# ATSAM4N16C device description
Architecture: CORTEX-M4; Family: SAM4; Series: SAM4N
Registers are 32-bit, read-write, no defined reset value unless marked. A register's access mark holds for its fields unless they carry their own. Offsets are from the block's base; [hi:lo] are bit positions; {n}, {i} and the like mark numbered series; 'fields as' and 'values as' point back to an identical list.

## TC — Timer Counter
Instances: TC0 0x40010000, TC1 0x40014000
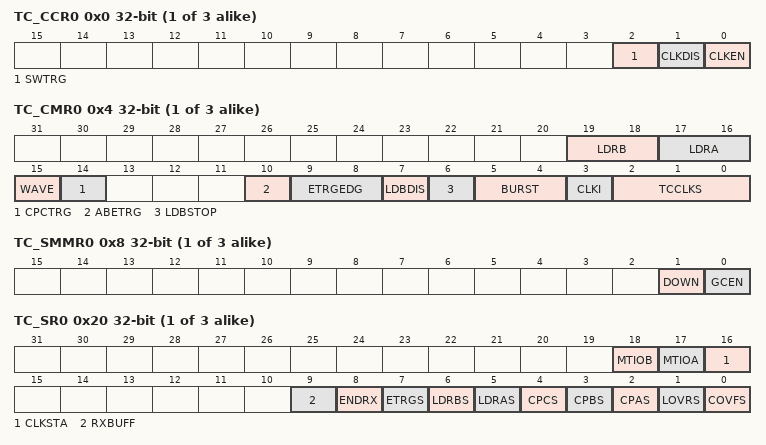
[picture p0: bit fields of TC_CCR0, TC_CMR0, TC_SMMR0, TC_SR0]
{0x0+0x40*i} TC_CCR{i} wo (i=0..2) — Channel Control Register (channel = {i})
  [2] SWTRG — Software Trigger Command
  [1] CLKDIS — Counter Clock Disable Command
  [0] CLKEN — Counter Clock Enable Command
{0x4+0x40*i} TC_CMR{i} (i=0..2) — Channel Mode Register (channel = {i})
  [19:18] LDRB — RB Loading Edge Selection
    0=NONE; 1=RISING (Rising edge of TIOA); 2=FALLING (Falling edge of TIOA); 3=EDGE (Each edge of TIOA)
  [17:16] LDRA — RA Loading Edge Selection
    values as LDRB
  [15] WAVE — Waveform Mode
  [14] CPCTRG — RC Compare Trigger Enable
  [10] ABETRG — TIOA or TIOB External Trigger Selection
  [9:8] ETRGEDG — External Trigger Edge Selection
    0=NONE (The clock is not gated by an external signal.); 1=RISING (Rising edge); 2=FALLING (Falling edge); 3=EDGE (Each edge)
  [7] LDBDIS — Counter Clock Disable with RB Loading
  [6] LDBSTOP — Counter Clock Stopped with RB Loading
  [5:4] BURST — Burst Signal Selection
    0=NONE (The clock is not gated by an external signal.); 1=XC0 (XC0 is ANDed with the selected clock.); 2=XC1 (XC1 is ANDed with the selected clock.); 3=XC2 (XC2 is ANDed with the selected clock.)
  [3] CLKI — Clock Invert
  [2:0] TCCLKS — Clock Selection
    0=TIMER_CLOCK1 (Clock selected: internal MCK/2 clock signal (from PMC)); 1=TIMER_CLOCK2 (Clock selected: internal MCK/8 clock signal (from PMC)); 2=TIMER_CLOCK3 (Clock selected: internal MCK/32 clock signal (from PMC)); 3=TIMER_CLOCK4 (Clock selected: internal MCK/128 clock signal (from PMC)); 4=TIMER_CLOCK5 (Clock selected: internal SLCK clock signal (from PMC)); 5=XC0 (Clock selected: XC0); 6=XC1 (Clock selected: XC1); 7=XC2 (Clock selected: XC2)
{0x8+0x40*i} TC_SMMR{i} (i=0..2) — Stepper Motor Mode Register (channel = {i})
  [1] DOWN — Down Count
  [0] GCEN — Gray Count Enable
{0x10+0x40*i} TC_CV{i} ro (i=0..2) — Counter Value (channel = {i})
  [31:0] CV — Counter Value
{0x14+0x40*i} TC_RA{i} (i=0..2) — Register A (channel = {i})
  [31:0] RA — Register A
{0x18+0x40*i} TC_RB{i} (i=0..2) — Register B (channel = {i})
  [31:0] RB — Register B
{0x1C+0x40*i} TC_RC{i} (i=0..2) — Register C (channel = {i})
  [31:0] RC — Register C
{0x20+0x40*i} TC_SR{i} ro (i=0..2) — Status Register (channel = {i})
  [18] MTIOB — TIOB Mirror
  [17] MTIOA — TIOA Mirror
  [16] CLKSTA — Clock Enabling Status
  [9] RXBUFF — Reception Buffer Full (cleared by writing TC_RCR or TC_RNCR)
  [8] ENDRX — End of Receiver Transfer (cleared by writing TC_RCR or TC_RNCR)
  [7] ETRGS — External Trigger Status (cleared on read)
  [6] LDRBS — RB Loading Status (cleared on read)
  [5] LDRAS — RA Loading Status (cleared on read)
  [4] CPCS — RC Compare Status (cleared on read)
  [3] CPBS — RB Compare Status (cleared on read)
  [2] CPAS — RA Compare Status (cleared on read)
  [1] LOVRS — Load Overrun Status (cleared on read)
  [0] COVFS — Counter Overflow Status (cleared on read)
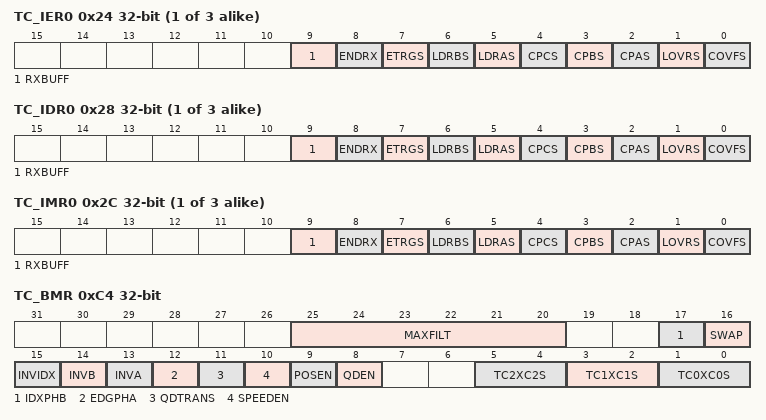
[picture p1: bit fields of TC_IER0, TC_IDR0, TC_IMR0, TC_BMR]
{0x24+0x40*i} TC_IER{i} wo (i=0..2) — Interrupt Enable Register (channel = {i})
  [9] RXBUFF — Reception Buffer Full
  [8] ENDRX — End of Receiver Transfer
  [7] ETRGS — External Trigger
  [6] LDRBS — RB Loading
  [5] LDRAS — RA Loading
  [4] CPCS — RC Compare
  [3] CPBS — RB Compare
  [2] CPAS — RA Compare
  [1] LOVRS — Load Overrun
  [0] COVFS — Counter Overflow
{0x28+0x40*i} TC_IDR{i} wo (i=0..2) — Interrupt Disable Register (channel = {i})
  fields as TC_IER0
{0x2C+0x40*i} TC_IMR{i} ro (i=0..2) — Interrupt Mask Register (channel = {i})
  fields as TC_IER0
0xC0 TC_BCR wo — Block Control Register
  [0] SYNC — Synchro Command
0xC4 TC_BMR — Block Mode Register
  [25:20] MAXFILT — Maximum Filter
  [17] IDXPHB — Index Pin is PHB Pin
  [16] SWAP — Swap PHA and PHB
  [15] INVIDX — Inverted Index
  [14] INVB — Inverted PHB
  [13] INVA — Inverted PHA
  [12] EDGPHA — Edge on PHA Count Mode
  [11] QDTRANS — Quadrature Decoding Transparent
  [10] SPEEDEN — Speed Enabled
  [9] POSEN — Position Enabled
  [8] QDEN — Quadrature Decoder Enabled
  [5:4] TC2XC2S — External Clock Signal 2 Selection
    0=TCLK2 (Signal connected to XC2: TCLK2); 2=TIOA0 (Signal connected to XC2: TIOA0); 3=TIOA1 (Signal connected to XC2: TIOA1)
  [3:2] TC1XC1S — External Clock Signal 1 Selection
    0=TCLK1 (Signal connected to XC1: TCLK1); 2=TIOA0 (Signal connected to XC1: TIOA0); 3=TIOA2 (Signal connected to XC1: TIOA2)
  [1:0] TC0XC0S — External Clock Signal 0 Selection
    0=TCLK0 (Signal connected to XC0: TCLK0); 2=TIOA1 (Signal connected to XC0: TIOA1); 3=TIOA2 (Signal connected to XC0: TIOA2)
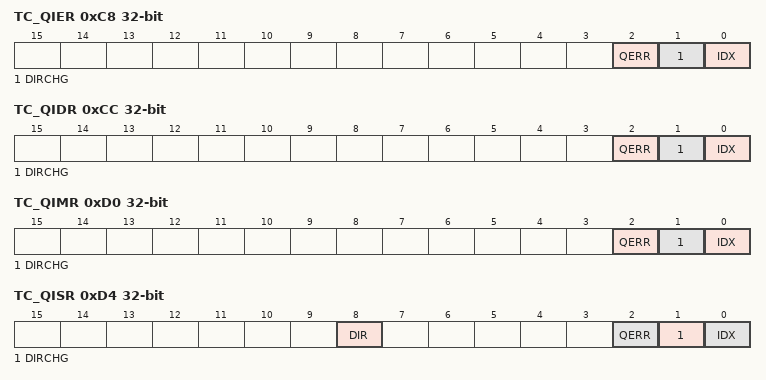
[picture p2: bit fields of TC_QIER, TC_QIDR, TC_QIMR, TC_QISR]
0xC8 TC_QIER wo — QDEC Interrupt Enable Register
  [2] QERR — Quadrature Error
  [1] DIRCHG — Direction Change
  [0] IDX — Index
0xCC TC_QIDR wo — QDEC Interrupt Disable Register
  fields as TC_QIER
0xD0 TC_QIMR ro — QDEC Interrupt Mask Register
  fields as TC_QIER
0xD4 TC_QISR ro — QDEC Interrupt Status Register
  [8] DIR — Direction
  [2] QERR — Quadrature Error
  [1] DIRCHG — Direction Change
  [0] IDX — Index
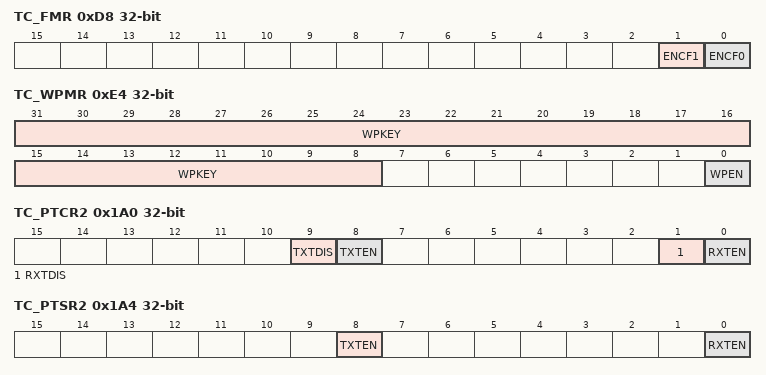
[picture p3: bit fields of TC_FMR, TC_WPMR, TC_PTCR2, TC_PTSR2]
0xD8 TC_FMR — Fault Mode Register
  [1] ENCF1 — Enable Compare Fault Channel 1
  [0] ENCF0 — Enable Compare Fault Channel 0
0xE4 TC_WPMR — Write Protection Mode Register
  [31:8] WPKEY — Write Protection Key
    0x54494D=PASSWD (Writing any other value in this field aborts the write operation of the WPEN bit.Always reads as 0.)
  [0] WPEN — Write Protection Enable
0x180 TC_RPR2 — Receive Pointer Register (pdc = 2)
  [31:0] RXPTR — Receive Pointer Register
0x184 TC_RCR2 — Receive Counter Register (pdc = 2)
  [15:0] RXCTR — Receive Counter Register
0x190 TC_RNPR2 — Receive Next Pointer Register (pdc = 2)
  [31:0] RXNPTR — Receive Next Pointer
0x194 TC_RNCR2 — Receive Next Counter Register (pdc = 2)
  [15:0] RXNCTR — Receive Next Counter
0x1A0 TC_PTCR2 wo — Transfer Control Register (pdc = 2)
  [9] TXTDIS — Transmitter Transfer Disable
  [8] TXTEN — Transmitter Transfer Enable
  [1] RXTDIS — Receiver Transfer Disable
  [0] RXTEN — Receiver Transfer Enable
0x1A4 TC_PTSR2 ro — Transfer Status Register (pdc = 2)
  [8] TXTEN — Transmitter Transfer Enable
  [0] RXTEN — Receiver Transfer Enable
